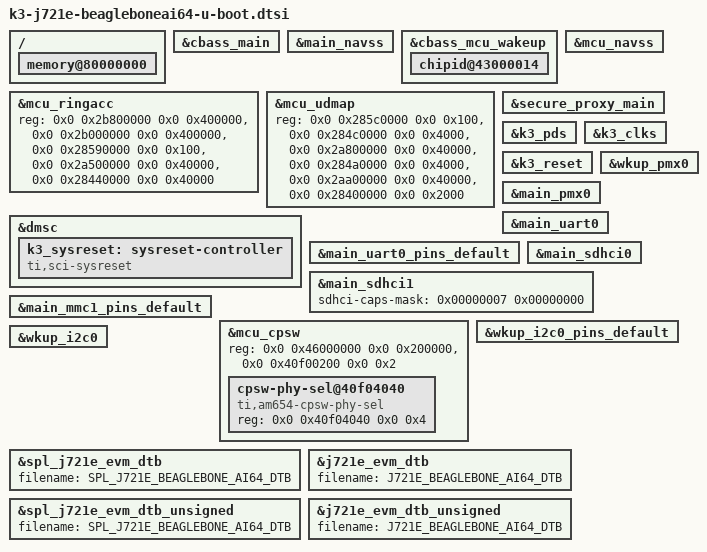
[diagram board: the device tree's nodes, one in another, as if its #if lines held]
// SPDX-License-Identifier: GPL-2.0
/*
 * https://beagleboard.org/ai-64
 *
 * Copyright (C) 2022-2023 Texas Instruments Incorporated - https://www.ti.com/
 * Copyright (C) 2022 Jason Kridner, BeagleBoard.org Foundation
 * Copyright (C) 2022-2023 Robert Nelson, BeagleBoard.org Foundation
 */

#include "k3-j721e-binman.dtsi"

/ {
	memory@80000000 {
		bootph-all;
	};
};

&cbass_main {
	bootph-all;
};

&main_navss {
	bootph-all;
};

&cbass_mcu_wakeup {
	bootph-all;

	chipid@43000014 {
		bootph-all;
	};
};

&mcu_navss {
	bootph-all;
};

&mcu_ringacc {
	reg = <0x0 0x2b800000 0x0 0x400000>,
		<0x0 0x2b000000 0x0 0x400000>,
		<0x0 0x28590000 0x0 0x100>,
		<0x0 0x2a500000 0x0 0x40000>,
		<0x0 0x28440000 0x0 0x40000>;
	reg-names = "rt", "fifos", "proxy_gcfg", "proxy_target", "cfg";
	bootph-all;
};

&mcu_udmap {
	reg = <0x0 0x285c0000 0x0 0x100>,
		<0x0 0x284c0000 0x0 0x4000>,
		<0x0 0x2a800000 0x0 0x40000>,
		<0x0 0x284a0000 0x0 0x4000>,
		<0x0 0x2aa00000 0x0 0x40000>,
		<0x0 0x28400000 0x0 0x2000>;
	reg-names = "gcfg", "rchan", "rchanrt", "tchan",
		"tchanrt", "rflow";
	bootph-all;
};

&secure_proxy_main {
	bootph-all;
};

&dmsc {
	bootph-all;
	k3_sysreset: sysreset-controller {
		compatible = "ti,sci-sysreset";
		bootph-all;
	};
};

&k3_pds {
	bootph-all;
};

&k3_clks {
	bootph-all;
};

&k3_reset {
	bootph-all;
};

&wkup_pmx0 {
	bootph-all;
};

&main_pmx0 {
	bootph-all;
};

&main_uart0 {
	bootph-all;
};

&main_uart0_pins_default {
	bootph-all;
};

&main_sdhci0 {
	bootph-all;
};

&main_sdhci1 {
	bootph-all;
	sdhci-caps-mask = <0x00000007 0x00000000>;
	/delete-property/ cd-gpios;
	/delete-property/ cd-debounce-delay-ms;
	/delete-property/ ti,fails-without-test-cd;
	/delete-property/ no-1-8-v;
};

&main_mmc1_pins_default {
	bootph-all;
};

&mcu_cpsw {
	reg = <0x0 0x46000000 0x0 0x200000>,
	      <0x0 0x40f00200 0x0 0x2>;
	reg-names = "cpsw_nuss", "mac_efuse";
	/delete-property/ ranges;

	cpsw-phy-sel@40f04040 {
		compatible = "ti,am654-cpsw-phy-sel";
		reg= <0x0 0x40f04040 0x0 0x4>;
		reg-names = "gmii-sel";
	};
};

&wkup_i2c0_pins_default {
	bootph-all;
};

&wkup_i2c0 {
	bootph-all;
};

#ifdef CONFIG_TARGET_J721E_A72_EVM

#define SPL_J721E_BEAGLEBONE_AI64_DTB "spl/dts/k3-j721e-beagleboneai64.dtb"
#define J721E_BEAGLEBONE_AI64_DTB "arch/arm/dts/k3-j721e-beagleboneai64.dtb"

&spl_j721e_evm_dtb {
	filename = SPL_J721E_BEAGLEBONE_AI64_DTB;
};

&j721e_evm_dtb {
	filename = J721E_BEAGLEBONE_AI64_DTB;
};

&spl_j721e_evm_dtb_unsigned {
	filename = SPL_J721E_BEAGLEBONE_AI64_DTB;
};

&j721e_evm_dtb_unsigned {
	filename = J721E_BEAGLEBONE_AI64_DTB;
};

#endif
